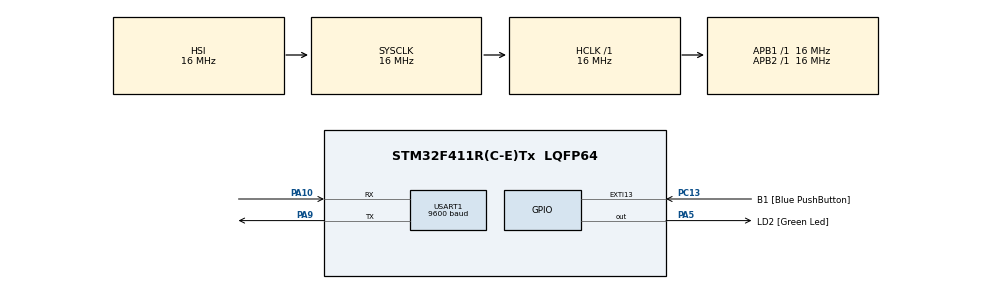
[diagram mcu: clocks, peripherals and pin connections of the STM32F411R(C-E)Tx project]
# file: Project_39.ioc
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FREERTOS.Tasks01=defaultTask,0,128,StartDefaultTask,Default,NULL,Dynamic,NULL,NULL
FREERTOS.configUSE_IDLE_HOOK=1
Mcu.Family=STM32F4
Mcu.Name=STM32F411R(C-E)Tx
Mcu.Package=LQFP64
NVIC.PriorityGroup=NVIC_PRIORITYGROUP_4
PA10.Mode=Asynchronous
PA10.Signal=USART1_RX
PA2.GPIO_Label=USART_TX
PA2.Signal=USART2_TX
PA3.GPIO_Label=USART_RX
PA3.Signal=USART2_RX
PA5.GPIO_Label=LD2 [Green Led]
PA5.Signal=GPIO_Output
PA9.Mode=Asynchronous
PA9.Signal=USART1_TX
PC13-ANTI_TAMP.GPIO_Label=B1 [Blue PushButton]
PC13-ANTI_TAMP.GPIO_ModeDefaultEXTI=GPIO_MODE_IT_FALLING
PC13-ANTI_TAMP.Signal=GPXTI13
ProjectManager.HeapSize=0x200
ProjectManager.StackSize=0x400
ProjectManager.TargetToolchain=MDK-ARM V5.27
RCC.48MHZClocksFreq_Value=84000000
RCC.AHBFreq_Value=16000000
RCC.APB1Freq_Value=16000000
RCC.APB1TimFreq_Value=16000000
RCC.APB2Freq_Value=16000000
RCC.APB2TimFreq_Value=16000000
RCC.CortexFreq_Value=16000000
RCC.FLatency-AdvancedSettings=FLASH_LATENCY_0
RCC.HCLKFreq_Value=16000000
RCC.HSE_VALUE=8000000
RCC.HSI_VALUE=16000000
RCC.LSE_VALUE=32768
RCC.PLLN=336
RCC.PLLP=RCC_PLLP_DIV4
RCC.SYSCLKFreq_VALUE=16000000
RCC.VCOOutputFreq_Value=336000000
USART1.BaudRate=9600
USART1.VirtualMode=VM_ASYNC
VP_FREERTOS_VS_CMSIS_V1.Mode=CMSIS_V1
board=NUCLEO-F411RE

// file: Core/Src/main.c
/* USER CODE BEGIN Header */
/**
  ******************************************************************************
  * @file           : main.c
  * @brief          : Main program body
  ******************************************************************************
  * @attention
  *
  * <h2><center>&copy; Copyright (c) 2021 STMicroelectronics.
  * All rights reserved.</center></h2>
  *
  * This software component is licensed by ST under Ultimate Liberty license
  * SLA0044, the "License"; You may not use this file except in compliance with
  * the License. You may obtain a copy of the License at:
  *                             www.st.com/SLA0044
  *
  ******************************************************************************
  */
/* USER CODE END Header */
#include "main.h"
#include "cmsis_os.h"
#include <string.h>
#include <stdio.h>

uint32_t counter = 0;
char uartBuf[100];
UART_HandleTypeDef huart1;
int led2 = 5;

void SystemClock_Config(void);
static void MX_GPIO_Init(void);
static void MX_USART1_UART_Init(void);
void task1(void*);

int main(void)
{

  /* MCU Configuration--------------------------------------------------------*/

  /* Reset of all peripherals, Initializes the Flash interface and the Systick. */
  HAL_Init();

  /* Configure the system clock */
  SystemClock_Config();

  /* Initialize all configured peripherals */
  MX_GPIO_Init();
  MX_USART1_UART_Init();

  /* Create the thread(s) */
	xTaskCreate(task1, "Task1", configMINIMAL_STACK_SIZE, NULL, 7, NULL);

  /* Start scheduler */
	vTaskStartScheduler();

  /* We should never get here as control is now taken by the scheduler */
  /* Infinite loop */
  while (1)
  {

  }
}

void SystemClock_Config(void)
{
  RCC_OscInitTypeDef RCC_OscInitStruct = {0};
  RCC_ClkInitTypeDef RCC_ClkInitStruct = {0};

  /** Configure the main internal regulator output voltage
  */
  __HAL_RCC_PWR_CLK_ENABLE();
  __HAL_PWR_VOLTAGESCALING_CONFIG(PWR_REGULATOR_VOLTAGE_SCALE1);
  /** Initializes the RCC Oscillators according to the specified parameters
  * in the RCC_OscInitTypeDef structure.
  */
  RCC_OscInitStruct.OscillatorType = RCC_OSCILLATORTYPE_HSI;
  RCC_OscInitStruct.HSIState = RCC_HSI_ON;
  RCC_OscInitStruct.HSICalibrationValue = RCC_HSICALIBRATION_DEFAULT;
  RCC_OscInitStruct.PLL.PLLState = RCC_PLL_NONE;
  if (HAL_RCC_OscConfig(&RCC_OscInitStruct) != HAL_OK)
  {
    Error_Handler();
  }
  /** Initializes the CPU, AHB and APB buses clocks
  */
  RCC_ClkInitStruct.ClockType = RCC_CLOCKTYPE_HCLK|RCC_CLOCKTYPE_SYSCLK
                              |RCC_CLOCKTYPE_PCLK1|RCC_CLOCKTYPE_PCLK2;
  RCC_ClkInitStruct.SYSCLKSource = RCC_SYSCLKSOURCE_HSI;
  RCC_ClkInitStruct.AHBCLKDivider = RCC_SYSCLK_DIV1;
  RCC_ClkInitStruct.APB1CLKDivider = RCC_HCLK_DIV1;
  RCC_ClkInitStruct.APB2CLKDivider = RCC_HCLK_DIV1;

  if (HAL_RCC_ClockConfig(&RCC_ClkInitStruct, FLASH_LATENCY_0) != HAL_OK)
  {
    Error_Handler();
  }
}

static void MX_USART1_UART_Init(void)
{

  huart1.Instance = USART1;
  huart1.Init.BaudRate = 9600;
  huart1.Init.WordLength = UART_WORDLENGTH_8B;
  huart1.Init.StopBits = UART_STOPBITS_1;
  huart1.Init.Parity = UART_PARITY_NONE;
  huart1.Init.Mode = UART_MODE_TX_RX;
  huart1.Init.HwFlowCtl = UART_HWCONTROL_NONE;
  huart1.Init.OverSampling = UART_OVERSAMPLING_16;
  if (HAL_UART_Init(&huart1) != HAL_OK)
  {
    Error_Handler();
  }

}

static void MX_GPIO_Init(void)
{
  GPIO_InitTypeDef GPIO_InitStruct = {0};

  /* GPIO Ports Clock Enable */
  __HAL_RCC_GPIOC_CLK_ENABLE();
  __HAL_RCC_GPIOA_CLK_ENABLE();

  /*Configure GPIO pin Output Level */
  HAL_GPIO_WritePin(LD2_GPIO_Port, LD2_Pin, GPIO_PIN_RESET);

  /*Configure GPIO pin : B1_Pin */
  GPIO_InitStruct.Pin = B1_Pin;
  GPIO_InitStruct.Mode = GPIO_MODE_IT_FALLING;
  GPIO_InitStruct.Pull = GPIO_NOPULL;
  HAL_GPIO_Init(B1_GPIO_Port, &GPIO_InitStruct);

  /*Configure GPIO pins : USART_TX_Pin USART_RX_Pin */
  GPIO_InitStruct.Pin = USART_TX_Pin|USART_RX_Pin;
  GPIO_InitStruct.Mode = GPIO_MODE_AF_PP;
  GPIO_InitStruct.Pull = GPIO_NOPULL;
  GPIO_InitStruct.Speed = GPIO_SPEED_FREQ_VERY_HIGH;
  GPIO_InitStruct.Alternate = GPIO_AF7_USART2;
  HAL_GPIO_Init(GPIOA, &GPIO_InitStruct);

  /*Configure GPIO pin : LD2_Pin */
  GPIO_InitStruct.Pin = LD2_Pin;
  GPIO_InitStruct.Mode = GPIO_MODE_OUTPUT_PP;
  GPIO_InitStruct.Pull = GPIO_NOPULL;
  GPIO_InitStruct.Speed = GPIO_SPEED_FREQ_LOW;
  HAL_GPIO_Init(LD2_GPIO_Port, &GPIO_InitStruct);

}

/* USER CODE BEGIN 4 */
void task1(void *param){

	while(1){
		HAL_GPIO_TogglePin(LD2_GPIO_Port, LD2_Pin);
		vTaskDelay( pdMS_TO_TICKS(100) );

		sprintf(uartBuf, "Counter  = %d\r\n", counter);
		HAL_UART_Transmit(&huart1, (uint8_t *)uartBuf, strlen(uartBuf), 100);
		counter = 0;
	}

}

void vApplicationIdleHook(void){
	++counter;
}

/* USER CODE END 4 */

void StartDefaultTask(void const * argument)
{
  for(;;)
  {
    osDelay(1);
  }
}

void Error_Handler(void)
{
  __disable_irq();
  while (1)
  {
  }
}

/************************ (C) COPYRIGHT STMicroelectronics *****END OF FILE****/

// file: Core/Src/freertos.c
/* USER CODE BEGIN Header */
/**
  ******************************************************************************
  * File Name          : freertos.c
  * Description        : Code for freertos applications
  ******************************************************************************
  * @attention
  *
  * <h2><center>&copy; Copyright (c) 2021 STMicroelectronics.
  * All rights reserved.</center></h2>
  *
  * This software component is licensed by ST under Ultimate Liberty license
  * SLA0044, the "License"; You may not use this file except in compliance with
  * the License. You may obtain a copy of the License at:
  *                             www.st.com/SLA0044
  *
  ******************************************************************************
  */
/* USER CODE END Header */

#include "FreeRTOS.h"
#include "task.h"
#include "main.h"

/* GetIdleTaskMemory prototype (linked to static allocation support) */
void vApplicationGetIdleTaskMemory( StaticTask_t **ppxIdleTaskTCBBuffer, StackType_t **ppxIdleTaskStackBuffer, uint32_t *pulIdleTaskStackSize );

/* Hook prototypes */
void vApplicationIdleHook(void);

/* USER CODE BEGIN 2 */
__weak void vApplicationIdleHook( void )
{
   /* vApplicationIdleHook() will only be called if configUSE_IDLE_HOOK is set
   to 1 in FreeRTOSConfig.h. It will be called on each iteration of the idle
   task. It is essential that code added to this hook function never attempts
   to block in any way (for example, call xQueueReceive() with a block time
   specified, or call vTaskDelay()). If the application makes use of the
   vTaskDelete() API function (as this demo application does) then it is also
   important that vApplicationIdleHook() is permitted to return to its calling
   function, because it is the responsibility of the idle task to clean up
   memory allocated by the kernel to any task that has since been deleted. */
}
/* USER CODE END 2 */

/* USER CODE BEGIN GET_IDLE_TASK_MEMORY */
static StaticTask_t xIdleTaskTCBBuffer;
static StackType_t xIdleStack[configMINIMAL_STACK_SIZE];

void vApplicationGetIdleTaskMemory( StaticTask_t **ppxIdleTaskTCBBuffer, StackType_t **ppxIdleTaskStackBuffer, uint32_t *pulIdleTaskStackSize )
{
  *ppxIdleTaskTCBBuffer = &xIdleTaskTCBBuffer;
  *ppxIdleTaskStackBuffer = &xIdleStack[0];
  *pulIdleTaskStackSize = configMINIMAL_STACK_SIZE;
  /* place for user code */
}
/* USER CODE END GET_IDLE_TASK_MEMORY */

/************************ (C) COPYRIGHT STMicroelectronics *****END OF FILE****/
